# w600 register map
File version: v0.1
Registers are 32-bit, read-write, reset 0x0 unless marked. A register's access mark holds for its fields unless they carry their own. Offsets are from the block's base; [hi:lo] are bit positions.

## 7816 — 7861/UART2
Base 0x40011C00
0x00 uart_line_ctrl reset 0x33520B — uart&7816 通信的数据相关设置
  [31:25] reserved — 保留
  [22:20] rx_retrans_cnt — 模式7816 卡 T0
  [18:16] tx_retrans_cnt — 模式7816 卡T0tx 自动重传次数
  [15:11] min_block_guard_time — 7816 卡的最小MIN_BGT（Min Block Guard Time ）Min Block Guard Time 计算： 10+stop 位(默认 2 位)+配置值MIN_BGT Note:T=0：在发送和接收的两个相反方向连续字符的起始位下降沿之间的最小时间间隔不能小于 16 个 ETU。必须能够正确解释接收到的其起始位下降沿和最后发送的字节起始位下降沿间隔为 15 个 ETU 的字符。T=1：在发送和接收的两个相反方向连续字符的起始位下降沿之间的最小时间间隔（块保护时间，BGT）必须为 22 个 ETU。必须能够正确解释接收到的其起始位下降沿和最后发送的字节起始位下降沿间隔为 21 个 ETU 以内接收到的字符。
  [0] sc_mode
    0=uart 模式; 1=7816 模式
  [0] rx_retrans_en — 模式7816 T0
    0=Rx 自动重传无效; 1=Rx 自动重传使能
  [0] tx_retrans_en
    0=Tx 自动重传无效; 1=Tx 自动重传使能
  [0] 7816_tmr_cfg — 7816 卡时钟控制配置
    0=在配置为卡模式时产生卡时钟输出，否则卡时钟输出无效; 1=时钟停止
  [0] 7816_parity_error — 7816 卡的parity 错误时是否接收数据
    0=不接收; 1=接收
  [0] 7816_mode — 7816 卡的T0/T1 模式配置，
    0=T0 模式; 1=T1 模式
  [0] uart_rx_enable — uart/7816 模式下，接收使能，高有效
  [0] uart_tx_enable — uart/7816 模式下，发送使能，高有效。
  [0] send_break_enable — 发送break 数据包。Uart 会在该为被置位后发送完一个break 数据包，发送完成后自动清 0。
  [0] parity
    0=偶校验; 1=奇校验; 0=LSB（b0 bit）先传输; 1=MSB（b7 bit）先传输
  [0] parity_en — 使能，高有效(UART 模式)
  [0] stop_bit_count — 个数（UART 模式）stop bit 个数（7816 模式）
    0=1 个停止位; 1=2 个停止位; 0=0.5 个停止位; 1=1.5 个停止位
  [1:0] uart_bit_length — 比特长度（UART 模式）
    0=5bit 2’h16bit 2’h27bit 2’h38bit
0x04 auto_flow_ctrl reset 0x14 — uart rts/cts 硬件流控设置
  [31:5] reserved — 保留
  [4:2] rts_trigger_level — （UART 模式）在afc_enable 有效时，决定何时需要将RTS 置无效。
    0=rxfifo 有 4 个以上字节 3’h1rxfifo 有 8 个以上字节 3’h2rxfifo 有 12 个以上字节 3’h3rxfifo 有 16 个以上字节 3’h4rxfifo 有 20 个以上字节 3’h5rxfifo 有 24 个以上字节 3’h6rxfifo 有 28 个以上字节; 7=rxfifo 有 31 个以上字节
  [0] rts_set — （UART 模式）当AFC_enable 无效时，软件可以通过设置此位来完成接收流量控制。当 AFC_enable有效时，此位不关心。
  [0] afc_enable — （UART 模式）接收条件rts 使用rts_trigger_level 控制产生，高有效。
0x08 dma_ctrl reset 0x24 — uart&7816 dma 传输模式设置
  [31:8] reserved — 保留
  [7:3] rxfifo_timeout_num — （UART 模式）rxfifo 中存在数据小于rxfifo_trigger_level 情况下，如果 N 个包的时间内，没有接收到新的数据时，产生rxfifo timeout 中断。该计时功能使能后，无论是第一次计时还是上一次计时完成，都只在接收到至少 1个包后才开始计时
  [0] rxfifo_timeout_en — （UART&7816 模式）rxfifo 超时使能，高有效
  [0] rx_dma_enable — （UART&7816 模式）接收DMA 使能，高有效。0 表示接收过程使用中断。
  [0] tx_dma_enable — （UART&7816 模式）发送DMA 使能，高有效。0 表示发送过程使用中断。
0x0C uart_fifo_ctrl reset 0x14 — 设置 uart&7816 fifo 触发等级
  [31:6] reserved — 保留
  [5:4] rxfifo_trigger_level — (UART&7816 模式)
    0=1byte; 1=4byte 2’h28byte; 3=16byte
  [3:2] txfifo_trigger_level — (UART&7816 模式)
    0=empty; 1=4byte 2’h28byte; 3=16byte
  [0] rxfifo_reset — (UART&7816 模式)复位rxfifo， 将rxfifo 状态清空
  [0] txfifo_reset — (UART&7816 模式)复位txfifo，将txfifo 状态清空
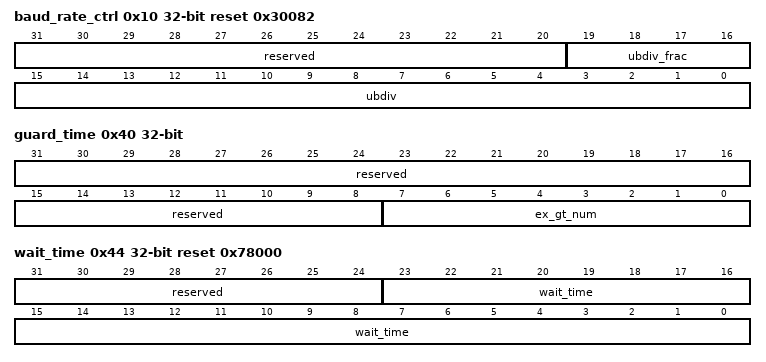
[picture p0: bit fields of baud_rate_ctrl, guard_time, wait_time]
0x10 baud_rate_ctrl reset 0x30082 — 设置uart 波特率、7816 时钟
  [31:20] reserved — 保留
  [19:16] ubdiv_frac — UART 模式：系统时钟除以 16 倍波特率时钟商的小数部分指示。具体值为frac×16 。（参考章节波特率计算方法）7816 模式：ubdiv_frac = (fclk_apb + fsc_clk)/(2 * fsc_clk) - 1;（参考 7816 时钟计算方法）
  [15:0] ubdiv — UART 模式：系统时钟除以 16 倍波特率时钟商的整数部分减 1。默认系统时钟为 40MHz，波特率为 19200。（参考波特率计算方法）7816 模式：ubdiv=Fi/Di (Fi、Di 为智能卡反馈的参数,edu 频率：f_etuclk = fsc_clk/(ubdiv+1))（参考章节 7816 速率计算方法）
0x14 int_mask reset 0x3FF — 设置uart&7816 需要使用的中断
  [31:10] reserved — 保留
  [0] 7816_error_signal — 卡发送时收到error signal 错误信号。（7816 模式）
  [0] overrun_error_int_mask — ， rxfifo 溢出中断屏蔽位，高有效。（UART&7816 模式）
  [0] parity_error_int_mask — ，奇偶检验中断屏蔽位，高有效。（UART&7816 模式）
  [0] frame_error_int_mask — ，数据帧出错中断屏蔽位，高有效。（UART 模式）
  [0] break_detect_int_mask — ，break 信号检测中断屏蔽位，高有效。（UART 模式）
  [0] cts_changed_indicate_mask — ，CTS 信号变化中断屏蔽位，高有效。（UART 模式）
  [0] rxfifo_data_timeout_int_mask — ，rxfifo 接收数据超时中断屏蔽位，高有效。（UART&7816 模式）
  [0] rxfifo_trigger_level_int_mask — ，rxfifo 达到触发值中断屏蔽位，高有效。（UART&7816 模式）
  [0] txfifo_trigger_level_int_mask — ，txfifo 达到触发值中断屏蔽位，高有效。（UART&7816 模式）
  [0] txfifo_empty_int_mask — ，txfifo 为空中断屏蔽位，高有效。（UART&7816 模式）
0x18 int_src — uart&7816 中断状态指示
  [31:9] reserved — 保留
  [0] 7816_error_signal — 卡发送时收到error signal 错误信号。(7816 模式)
  [0] overrun_error — （UART&7816 模式）rxfifo 出现溢出。 软件主动写 1 清 0。
  [0] parity_error — （UART&7816 模式）接收到的包校验位错误。DMA 情况下，此中断仍会产生。但DMA 操作不关心此中断。软件主动写 1 清 0。
  [0] frame_error — （UART 模式）接收到的包停止位错误。DMA 情况下，此中断仍会产生。但DMA 操作不关心此中断。软件主动写 1 清 0。
  [0] break_detect — （UART 模式）接收到break 包。DMA 情况下，此中断仍会产生。但DMA 操作不关心此中断。软件主动写 1 清 0。
  [0] cts_changed — （UART 模式）cts 信号变化则产生此中断。软件主动写 1 清 0。
  [0] rxfifo_data_timeout — （UART&7816 模式）rxfifo 中数据长度小于rxfifo trigger level 但N 个数据周期没有接收到任何数据，则产生中断。软件主动写 1 清 0。
  [0] rxfifo_trigger_level_interrupt — （UART&7816 模式）当rxfifo 中数据个数由小于rxfifo trigger level 中指定的数变成大于或等于该数时，产生此中断。此时应该根据rxfifo count 确定当前数据帧大小。软件主动写 1 清 0。
  [0] txfifo_trigger_level_interrupt — （UART&7816 模式）当txfifo 中数据个数由大于txfifo trigger level 中指定的数变成小于或等于该数时，产生中断。软件主动写 1 清 0。
  [0] tx_fifo_empty_interrupt — （UART&7816 模式）当发送完成当前包，并且txfifo 为空时，产生此中断。软件主动写 1 清 0。
0x1C fifo_status — fifo 状态，cts 状态查询
  [31:13] reserved — 保留
  [11:6] rxfifo_count — （UART&7816 模式）rxfifo 中数据个数
  [0] cts_status — （UART 模式）当前cts 的状态
  [5:0] txfifo_count — （UART&7816 模式）txfifo 中数据个数
0x20 tx_data_window
  [31:0] tx_data_window — （UART&7816 模式）发送数据起始地址。注意：uart 发送与接收数据只支持字节操作，当采用 burst 传输时，有可能使用字节地址递增的方式，设计中最多支持 16-burst 的操作，即 16byte。因此从发送/接收起始地址后共 16byte（4 个字）都保留为发送/接收数据窗口。
0x30 rx_data_window ro
  [31:0] rx_data_window — （UART&7816 模式）接收数据起始地址。注意：uart 发送与接收数据只支持字节操作，当采用 burst 传输时，有可能使用字节地址递增的方式，设计中最多支持 16-burst 的操作，即 16byte。因此从发送/接收起始地址后共 16byte（4 个字）都保留为发送/接收数据窗口。
0x40 guard_time — 7816 数据间保护时间
  [31:8] reserved — 保留
  [7:0] ex_gt_num — 7816 模式下，guard time 计算：10+stop 位+配置值ex_gt_num
0x44 wait_time reset 0x78000 — 7816 接收数据超时时间
  [31:24] reserved — 保留
  [23:0] wait_time — 计数器（以 ETU 为单位）7816 模式下：CWT 和BWT 时间，配置为最大默认值。（在 T1 模式下：BWT =（11 etu+ 2BWI*960*Fd/fsc））
